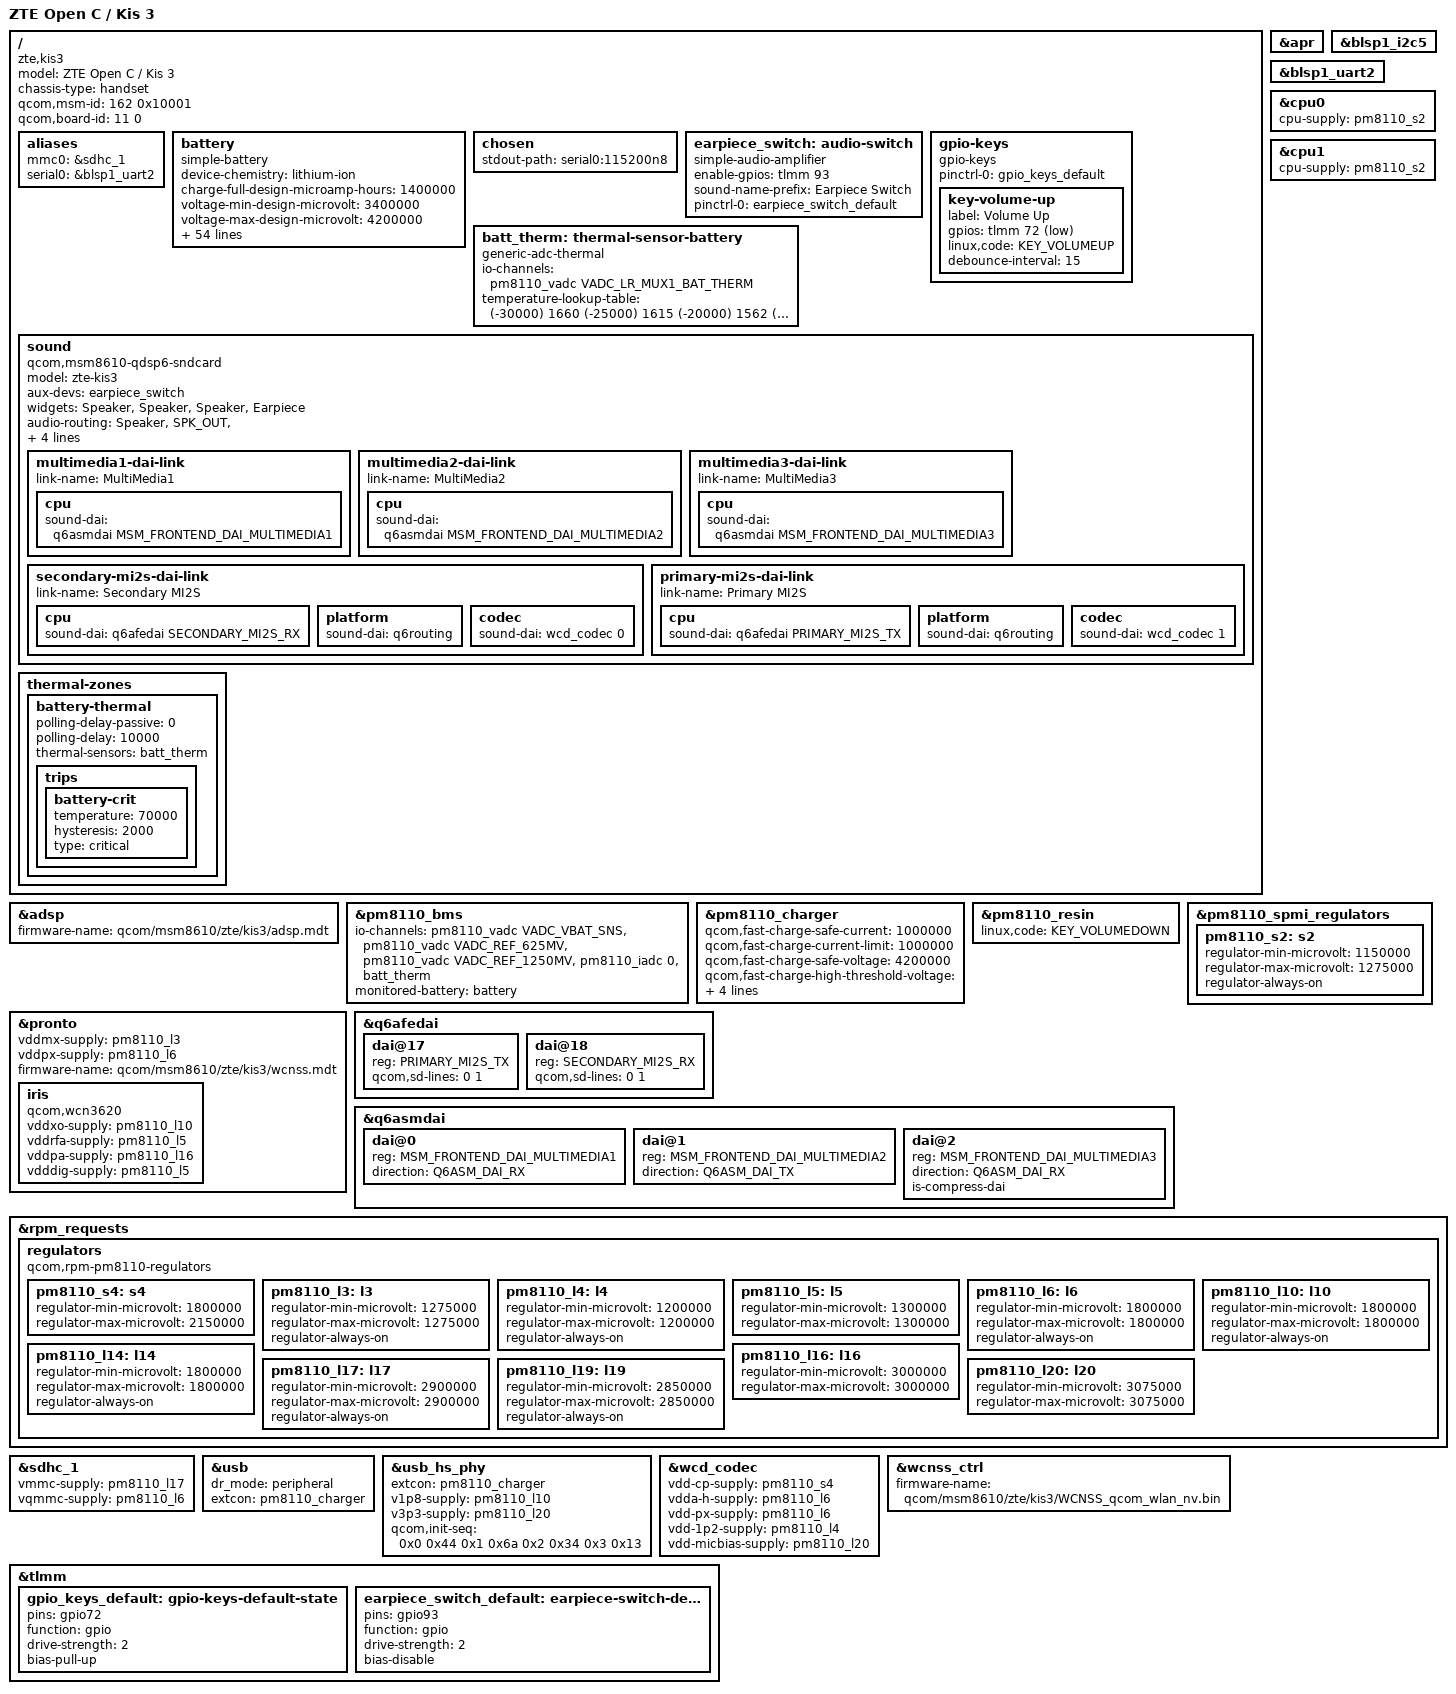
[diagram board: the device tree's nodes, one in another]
// SPDX-License-Identifier: BSD-3-Clause

#include <dt-bindings/gpio/gpio.h>
#include <dt-bindings/input/input.h>
#include <dt-bindings/sound/qcom,q6afe.h>
#include <dt-bindings/sound/qcom,q6asm.h>

#include "qcom-msm8610.dtsi"
#include "pm8110.dtsi"

/ {
	model = "ZTE Open C / Kis 3";
	compatible = "zte,kis3", "qcom,msm8210", "qcom,msm8610";
	chassis-type = "handset";

	qcom,msm-id = <162 0x10001>;
	qcom,board-id = <11 0>;

	aliases {
		mmc0 = &sdhc_1;
		serial0 = &blsp1_uart2;
	};

	/* ZTE 554846 cell, from the downstream battery profile */
	battery: battery {
		compatible = "simple-battery";
		device-chemistry = "lithium-ion";
		charge-full-design-microamp-hours = <1400000>;
		voltage-min-design-microvolt = <3400000>;
		voltage-max-design-microvolt = <4200000>;
		factory-internal-resistance-micro-ohms = <172000>;
		resistance-temp-table = <60 84>, <40 90>, <25 102>, <0 195>,
					<(-20) 613>;

		ocv-capacity-celsius = <(-20) 0 25 40 60>;
		ocv-capacity-table-0 = <4183000 100>, <4114000 95>, <4063000 90>, <4000000 85>,
				       <3949000 80>, <3915000 75>, <3884000 70>, <3854000 65>,
				       <3827000 60>, <3804000 55>, <3784000 50>, <3769000 45>,
				       <3758000 40>, <3748000 35>, <3739000 30>, <3729000 25>,
				       <3717000 20>, <3705000 16>, <3690000 13>, <3677000 11>,
				       <3669000 10>, <3659000 9>, <3647000 8>, <3631000 7>,
				       <3609000 6>, <3579000 5>, <3537000 4>, <3477000 3>,
				       <3384000 2>, <3250000 1>, <3000000 0>;
		ocv-capacity-table-1 = <4164000 100>, <4109000 95>, <4065000 90>, <4013000 85>,
				       <3969000 80>, <3931000 75>, <3896000 70>, <3866000 65>,
				       <3841000 60>, <3820000 55>, <3802000 50>, <3786000 45>,
				       <3775000 40>, <3766000 35>, <3758000 30>, <3746000 25>,
				       <3728000 20>, <3712000 16>, <3700000 13>, <3693000 11>,
				       <3690000 10>, <3686000 9>, <3680000 8>, <3672000 7>,
				       <3653000 6>, <3618000 5>, <3569000 4>, <3504000 3>,
				       <3416000 2>, <3293000 1>, <3000000 0>;
		ocv-capacity-table-2 = <4175000 100>, <4114000 95>, <4069000 90>, <4025000 85>,
				       <3987000 80>, <3954000 75>, <3923000 70>, <3892000 65>,
				       <3855000 60>, <3825000 55>, <3806000 50>, <3791000 45>,
				       <3779000 40>, <3771000 35>, <3764000 30>, <3749000 25>,
				       <3731000 20>, <3710000 16>, <3688000 13>, <3682000 11>,
				       <3680000 10>, <3678000 9>, <3675000 8>, <3670000 7>,
				       <3654000 6>, <3619000 5>, <3569000 4>, <3506000 3>,
				       <3424000 2>, <3293000 1>, <3000000 0>;
		ocv-capacity-table-3 = <4172000 100>, <4112000 95>, <4066000 90>, <4024000 85>,
				       <3986000 80>, <3952000 75>, <3921000 70>, <3893000 65>,
				       <3857000 60>, <3825000 55>, <3805000 50>, <3790000 45>,
				       <3779000 40>, <3770000 35>, <3758000 30>, <3741000 25>,
				       <3722000 20>, <3701000 16>, <3680000 13>, <3674000 11>,
				       <3673000 10>, <3670000 9>, <3667000 8>, <3662000 7>,
				       <3645000 6>, <3610000 5>, <3561000 4>, <3499000 3>,
				       <3417000 2>, <3280000 1>, <3000000 0>;
		ocv-capacity-table-4 = <4166000 100>, <4109000 95>, <4062000 90>, <4021000 85>,
				       <3982000 80>, <3948000 75>, <3917000 70>, <3889000 65>,
				       <3855000 60>, <3823000 55>, <3802000 50>, <3788000 45>,
				       <3776000 40>, <3766000 35>, <3750000 30>, <3727000 25>,
				       <3708000 20>, <3687000 16>, <3667000 13>, <3662000 11>,
				       <3660000 10>, <3659000 9>, <3655000 8>, <3648000 7>,
				       <3629000 6>, <3592000 5>, <3543000 4>, <3483000 3>,
				       <3399000 2>, <3262000 1>, <3000000 0>;
	};

	chosen {
		stdout-path = "serial0:115200n8";
	};

	/* Connects the earpiece to the codec EAR output */
	earpiece_switch: audio-switch {
		compatible = "simple-audio-amplifier";
		enable-gpios = <&tlmm 93 GPIO_ACTIVE_HIGH>;
		sound-name-prefix = "Earpiece Switch";

		pinctrl-0 = <&earpiece_switch_default>;
		pinctrl-names = "default";
	};

	gpio-keys {
		compatible = "gpio-keys";

		pinctrl-0 = <&gpio_keys_default>;
		pinctrl-names = "default";

		key-volume-up {
			label = "Volume Up";
			gpios = <&tlmm 72 GPIO_ACTIVE_LOW>;
			linux,code = <KEY_VOLUMEUP>;
			debounce-interval = <15>;
		};
	};

	/* Battery pack thermistor network, in mV of the 1.8 V reference */
	batt_therm: thermal-sensor-battery {
		compatible = "generic-adc-thermal";
		#thermal-sensor-cells = <0>;
		#io-channel-cells = <0>;
		io-channels = <&pm8110_vadc VADC_LR_MUX1_BAT_THERM>;
		io-channel-names = "sensor-channel";
		temperature-lookup-table = <(-30000) 1660
					    (-25000) 1615
					    (-20000) 1562
					    (-15000) 1499
					    (-10000) 1427
					    (-5000)  1349
					    0        1267
					    5000     1182
					    10000    1099
					    15000    1019
					    20000    944
					    25000    876
					    30000    816
					    35000    763
					    40000    717
					    45000    677
					    50000    644
					    55000    616
					    60000    592
					    65000    572
					    70000    555
					    75000    541
					    80000    530>;
	};

	sound {
		compatible = "qcom,msm8610-qdsp6-sndcard";
		model = "zte-kis3";

		aux-devs = <&earpiece_switch>;
		widgets = "Speaker", "Speaker",
			  "Speaker", "Earpiece";
		audio-routing = "Speaker", "SPK_OUT",
				"Earpiece Switch INL", "EAR",
				"Earpiece", "Earpiece Switch OUTL",
				"Headphone Jack", "HEADPHONE",
				"AMIC1", "MIC BIAS Internal1",
				"AMIC2", "MIC BIAS Internal2";

		multimedia1-dai-link {
			link-name = "MultiMedia1";

			cpu {
				sound-dai = <&q6asmdai MSM_FRONTEND_DAI_MULTIMEDIA1>;
			};
		};

		multimedia2-dai-link {
			link-name = "MultiMedia2";

			cpu {
				sound-dai = <&q6asmdai MSM_FRONTEND_DAI_MULTIMEDIA2>;
			};
		};

		multimedia3-dai-link {
			link-name = "MultiMedia3";

			cpu {
				sound-dai = <&q6asmdai MSM_FRONTEND_DAI_MULTIMEDIA3>;
			};
		};

		secondary-mi2s-dai-link {
			link-name = "Secondary MI2S";

			cpu {
				sound-dai = <&q6afedai SECONDARY_MI2S_RX>;
			};

			platform {
				sound-dai = <&q6routing>;
			};

			codec {
				sound-dai = <&wcd_codec 0>;
			};
		};

		primary-mi2s-dai-link {
			link-name = "Primary MI2S";

			cpu {
				sound-dai = <&q6afedai PRIMARY_MI2S_TX>;
			};

			platform {
				sound-dai = <&q6routing>;
			};

			codec {
				sound-dai = <&wcd_codec 1>;
			};
		};
	};

	thermal-zones {
		battery-thermal {
			polling-delay-passive = <0>;
			polling-delay = <10000>;
			thermal-sensors = <&batt_therm>;

			trips {
				battery-crit {
					temperature = <70000>;
					hysteresis = <2000>;
					type = "critical";
				};
			};
		};
	};
};

&adsp {
	firmware-name = "qcom/msm8610/zte/kis3/adsp.mdt";

	status = "okay";
};

&apr {
	status = "okay";
};

&blsp1_i2c5 {
	status = "okay";
};

&blsp1_uart2 {
	status = "okay";
};

&cpu0 {
	cpu-supply = <&pm8110_s2>;
};

&cpu1 {
	cpu-supply = <&pm8110_s2>;
};

&pm8110_bms {
	io-channels = <&pm8110_vadc VADC_VBAT_SNS>,
		      <&pm8110_vadc VADC_REF_625MV>,
		      <&pm8110_vadc VADC_REF_1250MV>,
		      <&pm8110_iadc 0>,
		      <&batt_therm>;
	io-channel-names = "vbat",
			   "ref_625mv",
			   "ref_1250mv",
			   "iadc",
			   "temp";
	monitored-battery = <&battery>;

	status = "okay";
};

&pm8110_charger {
	/* The bootloader locks the safe limits at these values */
	qcom,fast-charge-safe-current = <1000000>;
	qcom,fast-charge-current-limit = <1000000>;
	qcom,fast-charge-safe-voltage = <4200000>;
	qcom,fast-charge-high-threshold-voltage = <4200000>;
	qcom,auto-recharge-threshold-voltage = <4100000>;
	qcom,minimum-input-voltage = <4300000>;
	usb-charge-current-limit = <500000>;

	status = "okay";
};

&pm8110_resin {
	linux,code = <KEY_VOLUMEDOWN>;

	status = "okay";
};

&pm8110_spmi_regulators {
	/* CPU (APC) rail */
	pm8110_s2: s2 {
		regulator-min-microvolt = <1150000>;
		regulator-max-microvolt = <1275000>;
		regulator-always-on;
	};
};

&pronto {
	vddmx-supply = <&pm8110_l3>;
	vddpx-supply = <&pm8110_l6>;

	firmware-name = "qcom/msm8610/zte/kis3/wcnss.mdt";

	status = "okay";

	iris {
		compatible = "qcom,wcn3620";

		vddxo-supply = <&pm8110_l10>;
		vddrfa-supply = <&pm8110_l5>;
		vddpa-supply = <&pm8110_l16>;
		vdddig-supply = <&pm8110_l5>;
	};
};

&q6afedai {
	dai@17 {
		reg = <PRIMARY_MI2S_TX>;
		qcom,sd-lines = <0 1>;
	};

	dai@18 {
		reg = <SECONDARY_MI2S_RX>;
		qcom,sd-lines = <0 1>;
	};
};

&q6asmdai {
	dai@0 {
		reg = <MSM_FRONTEND_DAI_MULTIMEDIA1>;
		direction = <Q6ASM_DAI_RX>;
	};

	dai@1 {
		reg = <MSM_FRONTEND_DAI_MULTIMEDIA2>;
		direction = <Q6ASM_DAI_TX>;
	};

	dai@2 {
		reg = <MSM_FRONTEND_DAI_MULTIMEDIA3>;
		direction = <Q6ASM_DAI_RX>;
		is-compress-dai;
	};
};

&rpm_requests {
	regulators {
		compatible = "qcom,rpm-pm8110-regulators";

		/*
		 * Only rails with a known use are listed, at the downstream
		 * voltages; the rest are left to the RPM and other masters.
		 */

		/* Audio codec charge pump */
		pm8110_s4: s4 {
			regulator-min-microvolt = <1800000>;
			regulator-max-microvolt = <2150000>;
		};

		/*
		 * Memory (MX) rail; must not be below the CPU corner
		 * ceiling, which is 1.275 V for the turbo frequencies
		 */
		pm8110_l3: l3 {
			regulator-min-microvolt = <1275000>;
			regulator-max-microvolt = <1275000>;
			regulator-always-on;
		};

		/* DSI; no display driver yet, keep the bootloader setup alive */
		pm8110_l4: l4 {
			regulator-min-microvolt = <1200000>;
			regulator-max-microvolt = <1200000>;
			regulator-always-on;
		};

		/* WCN3620 RF and digital */
		pm8110_l5: l5 {
			regulator-min-microvolt = <1300000>;
			regulator-max-microvolt = <1300000>;
		};

		/* 1.8V I/O: eMMC pads, display, audio, WCNSS */
		pm8110_l6: l6 {
			regulator-min-microvolt = <1800000>;
			regulator-max-microvolt = <1800000>;
			regulator-always-on;
		};

		/* PLLs (incl. CPU), USB PHY, WCNSS */
		pm8110_l10: l10 {
			regulator-min-microvolt = <1800000>;
			regulator-max-microvolt = <1800000>;
			regulator-always-on;
		};

		/* Panel and I2C peripherals I/O */
		pm8110_l14: l14 {
			regulator-min-microvolt = <1800000>;
			regulator-max-microvolt = <1800000>;
			regulator-always-on;
		};

		/* WCN3620 PA */
		pm8110_l16: l16 {
			regulator-min-microvolt = <3000000>;
			regulator-max-microvolt = <3000000>;
		};

		/* eMMC */
		pm8110_l17: l17 {
			regulator-min-microvolt = <2900000>;
			regulator-max-microvolt = <2900000>;
			regulator-always-on;
		};

		/* DSI analog, sensors */
		pm8110_l19: l19 {
			regulator-min-microvolt = <2850000>;
			regulator-max-microvolt = <2850000>;
			regulator-always-on;
		};

		/* USB PHY */
		pm8110_l20: l20 {
			regulator-min-microvolt = <3075000>;
			regulator-max-microvolt = <3075000>;
		};
	};
};

&sdhc_1 {
	vmmc-supply = <&pm8110_l17>;
	vqmmc-supply = <&pm8110_l6>;

	status = "okay";
};

&usb {
	dr_mode = "peripheral";
	extcon = <&pm8110_charger>;

	status = "okay";
};

&usb_hs_phy {
	extcon = <&pm8110_charger>;
	v1p8-supply = <&pm8110_l10>;
	v3p3-supply = <&pm8110_l20>;

	qcom,init-seq = /bits/ 8 <0x0 0x44 0x1 0x6a 0x2 0x34 0x3 0x13>;
};

&wcd_codec {
	vdd-cp-supply = <&pm8110_s4>;
	vdda-h-supply = <&pm8110_l6>;
	vdd-px-supply = <&pm8110_l6>;
	vdd-1p2-supply = <&pm8110_l4>;
	vdd-micbias-supply = <&pm8110_l20>;

	status = "okay";
};

&wcnss_ctrl {
	firmware-name = "qcom/msm8610/zte/kis3/WCNSS_qcom_wlan_nv.bin";
};

&tlmm {
	gpio_keys_default: gpio-keys-default-state {
		pins = "gpio72";
		function = "gpio";
		drive-strength = <2>;
		bias-pull-up;
	};

	earpiece_switch_default: earpiece-switch-default-state {
		pins = "gpio93";
		function = "gpio";
		drive-strength = <2>;
		bias-disable;
	};
};
